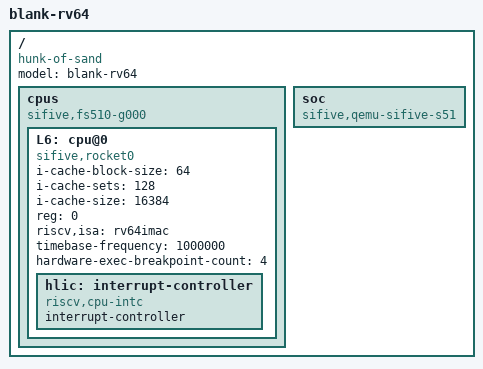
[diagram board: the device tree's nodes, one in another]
/dts-v1/;

/ {
        #address-cells = <1>;
        #size-cells = <1>;
        compatible = "hunk-of-sand";
        model = "blank-rv64";

        cpus {
                #address-cells = <1>;
                #size-cells = <0>;
                compatible = "sifive,fs510-g000";
                L6: cpu@0 {
                        compatible = "sifive,rocket0", "riscv";
                        device_type = "cpu";
                        i-cache-block-size = <64>;
                        i-cache-sets = <128>;
                        i-cache-size = <16384>;
                        reg = <0>;
                        riscv,isa = "rv64imac";
                        status = "okay";
                        timebase-frequency = <1000000>;
                        hardware-exec-breakpoint-count = <4>;
                        hlic: interrupt-controller {
                                #interrupt-cells = <1>;
                                compatible = "riscv,cpu-intc";
                                interrupt-controller;
                        };
                };
        };

        soc {
                #address-cells = <2>;
                #size-cells = <2>;
                #clock-cells = <1>;
                compatible = "sifive,qemu-sifive-s51";
        };
};
